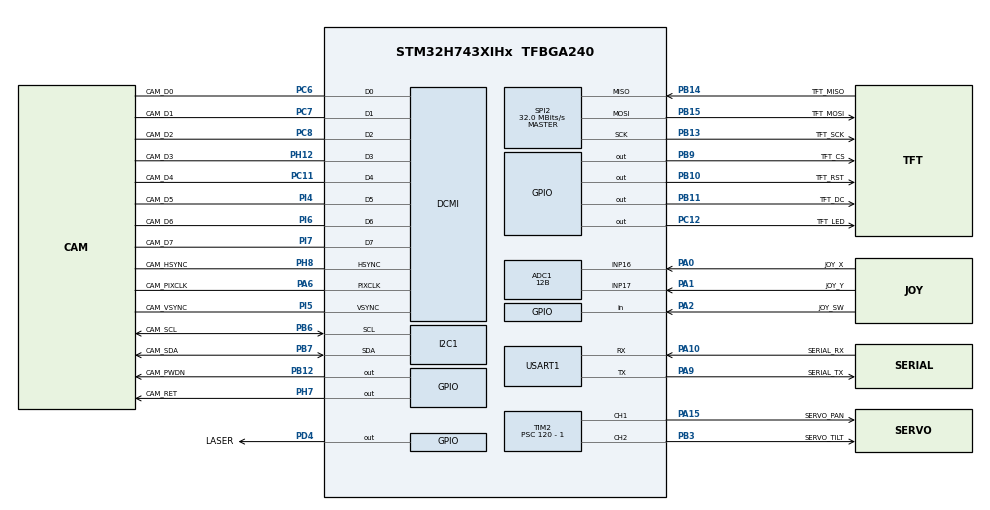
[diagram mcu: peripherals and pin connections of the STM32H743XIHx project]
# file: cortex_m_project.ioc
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ADC1.Channel-0\#ChannelRegularConversion=ADC_CHANNEL_16
ADC1.Channel-1\#ChannelRegularConversion=ADC_CHANNEL_17
ADC1.ClockPrescaler=ADC_CLOCK_ASYNC_DIV4
ADC1.ContinuousConvMode=ENABLE
ADC1.ConversionDataManagement=ADC_CONVERSIONDATA_DMA_CIRCULAR
ADC1.NbrOfConversion=2
ADC1.NbrOfConversionFlag=1
ADC1.OffsetNumber-0\#ChannelRegularConversion=ADC_OFFSET_NONE
ADC1.OffsetNumber-1\#ChannelRegularConversion=ADC_OFFSET_NONE
ADC1.OffsetSignedSaturation-0\#ChannelRegularConversion=DISABLE
ADC1.Rank-0\#ChannelRegularConversion=1
ADC1.Rank-1\#ChannelRegularConversion=2
ADC1.Resolution=ADC_RESOLUTION_12B
ADC1.SamplingTime-0\#ChannelRegularConversion=ADC_SAMPLETIME_64CYCLES_5
ADC1.SamplingTime-1\#ChannelRegularConversion=ADC_SAMPLETIME_64CYCLES_5
ADC1.master=1
CORTEX_M7.CPU_DCache=Enabled
CORTEX_M7.CPU_ICache=Enabled
CORTEX_M7.default_mode_Activation=1
DCMI.HSPolarity=DCMI_HSPOLARITY_LOW
DCMI.PCKPolarity=DCMI_PCKPOLARITY_RISING
DCMI.VSPolarity=DCMI_VSPOLARITY_LOW
Dma.ADC1.2.Direction=DMA_PERIPH_TO_MEMORY
Dma.ADC1.2.EventEnable=DISABLE
Dma.ADC1.2.FIFOMode=DMA_FIFOMODE_DISABLE
Dma.ADC1.2.Instance=DMA1_Stream2
Dma.ADC1.2.MemDataAlignment=DMA_MDATAALIGN_HALFWORD
Dma.ADC1.2.MemInc=DMA_MINC_ENABLE
Dma.ADC1.2.Mode=DMA_CIRCULAR
Dma.ADC1.2.PeriphDataAlignment=DMA_PDATAALIGN_HALFWORD
Dma.ADC1.2.PeriphInc=DMA_PINC_DISABLE
Dma.ADC1.2.Polarity=HAL_DMAMUX_REQ_GEN_RISING
Dma.ADC1.2.Priority=DMA_PRIORITY_LOW
Dma.ADC1.2.RequestNumber=1
Dma.ADC1.2.SignalID=NONE
Dma.ADC1.2.SyncEnable=DISABLE
Dma.ADC1.2.SyncPolarity=HAL_DMAMUX_SYNC_NO_EVENT
Dma.ADC1.2.SyncRequestNumber=1
Dma.ADC1.2.SyncSignalID=NONE
Dma.DCMI.0.Direction=DMA_PERIPH_TO_MEMORY
Dma.DCMI.0.EventEnable=DISABLE
Dma.DCMI.0.FIFOMode=DMA_FIFOMODE_ENABLE
Dma.DCMI.0.FIFOThreshold=DMA_FIFO_THRESHOLD_HALFFULL
Dma.DCMI.0.Instance=DMA1_Stream0
Dma.DCMI.0.MemBurst=DMA_MBURST_SINGLE
Dma.DCMI.0.MemDataAlignment=DMA_MDATAALIGN_WORD
Dma.DCMI.0.MemInc=DMA_MINC_ENABLE
Dma.DCMI.0.Mode=DMA_CIRCULAR
Dma.DCMI.0.PeriphBurst=DMA_PBURST_SINGLE
Dma.DCMI.0.PeriphDataAlignment=DMA_PDATAALIGN_WORD
Dma.DCMI.0.PeriphInc=DMA_PINC_DISABLE
Dma.DCMI.0.Polarity=HAL_DMAMUX_REQ_GEN_RISING
Dma.DCMI.0.Priority=DMA_PRIORITY_VERY_HIGH
Dma.DCMI.0.RequestNumber=1
Dma.DCMI.0.SignalID=NONE
Dma.DCMI.0.SyncEnable=DISABLE
Dma.DCMI.0.SyncPolarity=HAL_DMAMUX_SYNC_NO_EVENT
Dma.DCMI.0.SyncRequestNumber=1
Dma.DCMI.0.SyncSignalID=NONE
Dma.Request0=DCMI
Dma.Request1=SPI2_TX
Dma.Request2=ADC1
Dma.SPI2_TX.1.Direction=DMA_MEMORY_TO_PERIPH
Dma.SPI2_TX.1.EventEnable=DISABLE
Dma.SPI2_TX.1.FIFOMode=DMA_FIFOMODE_DISABLE
Dma.SPI2_TX.1.Instance=DMA1_Stream1
Dma.SPI2_TX.1.MemDataAlignment=DMA_MDATAALIGN_BYTE
Dma.SPI2_TX.1.MemInc=DMA_MINC_ENABLE
Dma.SPI2_TX.1.Mode=DMA_NORMAL
Dma.SPI2_TX.1.PeriphDataAlignment=DMA_PDATAALIGN_BYTE
Dma.SPI2_TX.1.PeriphInc=DMA_PINC_DISABLE
Dma.SPI2_TX.1.Polarity=HAL_DMAMUX_REQ_GEN_RISING
Dma.SPI2_TX.1.Priority=DMA_PRIORITY_MEDIUM
Dma.SPI2_TX.1.RequestNumber=1
Dma.SPI2_TX.1.SignalID=NONE
Dma.SPI2_TX.1.SyncEnable=DISABLE
Dma.SPI2_TX.1.SyncPolarity=HAL_DMAMUX_SYNC_NO_EVENT
Dma.SPI2_TX.1.SyncRequestNumber=1
Dma.SPI2_TX.1.SyncSignalID=NONE
FREERTOS.BinarySemaphores01=cameraFrameSem,Dynamic,NULL,Available
FREERTOS.Queues01=Queue1,1,12,1,Dynamic,NULL,NULL
FREERTOS.Tasks01=VisionTask,24,8192,StartVisionTask,Default,NULL,Dynamic,NULL,NULL;MotorTask,40,1024,StartMotorTask,Default,NULL,Dynamic,NULL,NULL
FREERTOS.configCHECK_FOR_STACK_OVERFLOW=2
FREERTOS.configTOTAL_HEAP_SIZE=131072
FREERTOS.configUSE_NEWLIB_REENTRANT=1
I2C1.Timing=0x307075B1
Mcu.Family=STM32H7
Mcu.Name=STM32H743XIHx
Mcu.Package=TFBGA240
NVIC.DCMI_IRQn=true\:5\:0\:false\:false\:true\:true\:true\:true\:true
NVIC.DMA1_Stream0_IRQn=true\:5\:0\:false\:false\:true\:true\:false\:true\:true
NVIC.DMA1_Stream1_IRQn=true\:5\:0\:false\:false\:true\:true\:false\:true\:true
NVIC.DMA1_Stream2_IRQn=true\:5\:0\:false\:false\:true\:true\:false\:true\:true
NVIC.PriorityGroup=NVIC_PRIORITYGROUP_4
NVIC.SPI2_IRQn=true\:5\:0\:false\:false\:true\:true\:true\:true\:true
NVIC.TIM6_DAC_IRQn=true\:15\:0\:false\:false\:true\:false\:false\:true\:true
NVIC.TimeBase=TIM6_DAC_IRQn
NVIC.TimeBaseIP=TIM6
NVIC.USART1_IRQn=true\:5\:0\:false\:false\:true\:true\:true\:true\:true
PA0.GPIO_Label=JOY_X
PA0.Mode=IN16-Single-Ended
PA0.Signal=ADC1_INP16
PA1.GPIO_Label=JOY_Y
PA1.Mode=IN17-Single-Ended
PA1.Signal=ADC1_INP17
PA10.GPIO_Label=SERIAL_RX
PA10.Mode=Asynchronous
PA10.Signal=USART1_RX
PA13\ (JTMS/SWDIO).Mode=Serial_Wire
PA13\ (JTMS/SWDIO).Signal=DEBUG_JTMS-SWDIO
PA14\ (JTCK/SWCLK).Mode=Serial_Wire
PA14\ (JTCK/SWCLK).Signal=DEBUG_JTCK-SWCLK
PA15\ (JTDI).GPIO_Label=SERVO_PAN
PA15\ (JTDI).Signal=S_TIM2_CH1_ETR
PA2.GPIO_Label=JOY_SW
PA2.GPIO_PuPd=GPIO_PULLUP
PA2.Signal=GPIO_Input
PA6.GPIO_Label=CAM_PIXCLK
PA6.GPIO_Speed=GPIO_SPEED_FREQ_VERY_HIGH
PA6.Mode=Slave_8_bits_External_Synchro
PA6.Signal=DCMI_PIXCLK
PA9.GPIO_Label=SERIAL_TX
PA9.Mode=Asynchronous
PA9.Signal=USART1_TX
PB10.GPIO_Label=TFT_RST
PB10.GPIO_Speed=GPIO_SPEED_FREQ_LOW
PB10.PinState=GPIO_PIN_SET
PB10.Signal=GPIO_Output
PB11.GPIO_Label=TFT_DC
PB11.GPIO_Speed=GPIO_SPEED_FREQ_HIGH
PB11.Signal=GPIO_Output
PB12.GPIO_Label=CAM_PWDN
PB12.Signal=GPIO_Output
PB13.GPIO_Label=TFT_SCK
PB13.Mode=Full_Duplex_Master
PB13.Signal=SPI2_SCK
PB14.GPIO_Label=TFT_MISO
PB14.Mode=Full_Duplex_Master
PB14.Signal=SPI2_MISO
PB15.GPIO_Label=TFT_MOSI
PB15.Mode=Full_Duplex_Master
PB15.Signal=SPI2_MOSI
PB3\ (JTDO/TRACESWO).GPIO_Label=SERVO_TILT
PB3\ (JTDO/TRACESWO).Signal=S_TIM2_CH2
PB6.GPIO_Label=CAM_SCL
PB6.GPIO_Pu=GPIO_PULLUP
PB6.Mode=I2C
PB6.Signal=I2C1_SCL
PB7.GPIO_Label=CAM_SDA
PB7.GPIO_Pu=GPIO_PULLUP
PB7.Mode=I2C
PB7.Signal=I2C1_SDA
PB9.GPIO_Label=TFT_CS
PB9.GPIO_Speed=GPIO_SPEED_FREQ_HIGH
PB9.PinState=GPIO_PIN_SET
PB9.Signal=GPIO_Output
PC11.GPIO_Label=CAM_D4
PC11.GPIO_Speed=GPIO_SPEED_FREQ_VERY_HIGH
PC11.Mode=Slave_8_bits_External_Synchro
PC11.Signal=DCMI_D4
PC12.GPIO_Label=TFT_LED
PC12.Signal=GPIO_Output
PC6.GPIO_Label=CAM_D0
PC6.GPIO_Speed=GPIO_SPEED_FREQ_VERY_HIGH
PC6.Mode=Slave_8_bits_External_Synchro
PC6.Signal=DCMI_D0
PC7.GPIO_Label=CAM_D1
PC7.GPIO_Speed=GPIO_SPEED_FREQ_VERY_HIGH
PC7.Mode=Slave_8_bits_External_Synchro
PC7.Signal=DCMI_D1
PC8.GPIO_Label=CAM_D2
PC8.GPIO_Speed=GPIO_SPEED_FREQ_VERY_HIGH
PC8.Mode=Slave_8_bits_External_Synchro
PC8.Signal=DCMI_D2
PD4.GPIO_Label=LASER
PD4.Signal=GPIO_Output
PH0-OSC_IN\ (PH0).Mode=HSE-External-Oscillator
PH0-OSC_IN\ (PH0).Signal=RCC_OSC_IN
PH1-OSC_OUT\ (PH1).Mode=HSE-External-Oscillator
PH1-OSC_OUT\ (PH1).Signal=RCC_OSC_OUT
PH12.GPIO_Label=CAM_D3
PH12.GPIO_Speed=GPIO_SPEED_FREQ_VERY_HIGH
PH12.Mode=Slave_8_bits_External_Synchro
PH12.Signal=DCMI_D3
PH7.GPIO_Label=CAM_RET
PH7.Signal=GPIO_Output
PH8.GPIO_Label=CAM_HSYNC
PH8.GPIO_Speed=GPIO_SPEED_FREQ_VERY_HIGH
PH8.Mode=Slave_8_bits_External_Synchro
PH8.Signal=DCMI_HSYNC
PI4.GPIO_Label=CAM_D5
PI4.GPIO_Speed=GPIO_SPEED_FREQ_VERY_HIGH
PI4.Mode=Slave_8_bits_External_Synchro
PI4.Signal=DCMI_D5
PI5.GPIO_Label=CAM_VSYNC
PI5.GPIO_Speed=GPIO_SPEED_FREQ_VERY_HIGH
PI5.Mode=Slave_8_bits_External_Synchro
PI5.Signal=DCMI_VSYNC
PI6.GPIO_Label=CAM_D6
PI6.GPIO_Speed=GPIO_SPEED_FREQ_VERY_HIGH
PI6.Mode=Slave_8_bits_External_Synchro
PI6.Signal=DCMI_D6
PI7.GPIO_Label=CAM_D7
PI7.GPIO_Speed=GPIO_SPEED_FREQ_VERY_HIGH
PI7.Mode=Slave_8_bits_External_Synchro
PI7.Signal=DCMI_D7
ProjectManager.HeapSize=0x20000
ProjectManager.StackSize=0x1000
ProjectManager.TargetToolchain=STM32CubeIDE
RCC.ADCFreq_Value=75000000
RCC.APB1Freq_Value=120000000
RCC.APB2Freq_Value=120000000
RCC.APB3Freq_Value=120000000
RCC.APB4Freq_Value=120000000
RCC.CortexFreq_Value=480000000
RCC.DIVM1=5
RCC.DIVM2=2
RCC.DIVN1=192
RCC.DIVN2=12
RCC.HCLKFreq_Value=120000000
RCC.HPRE=RCC_HCLK_DIV4
RCC.PLL2FRACN=0
RCC.PLL3FRACN=0
RCC.PLLFRACN=0
RCC.PLLSourceVirtual=RCC_PLLSOURCE_HSE
RCC.RCC_MCO1Source=RCC_MCO1SOURCE_HSE
RCC.RCC_MCODiv1=RCC_MCODIV_2
RCC.SPI123CLockSelection=RCC_SPI123CLKSOURCE_CLKP
RCC.SYSCLKFreq_VALUE=480000000
RCC.SYSCLKSource=RCC_SYSCLKSOURCE_PLLCLK
RCC.USBFreq_Value=480000000
SH.S_TIM2_CH1_ETR.0=TIM2_CH1,PWM Generation1 CH1
SH.S_TIM2_CH2.0=TIM2_CH2,PWM Generation2 CH2
SPI2.BaudRatePrescaler=SPI_BAUDRATEPRESCALER_2
SPI2.CalculateBaudRate=32.0 MBits/s
SPI2.DataSize=SPI_DATASIZE_8BIT
SPI2.Direction=SPI_DIRECTION_2LINES
SPI2.Mode=SPI_MODE_MASTER
SPI2.NSSPMode=SPI_NSS_PULSE_DISABLE
SPI2.VirtualType=VM_MASTER
TIM2.Channel-PWM\ Generation1\ CH1=TIM_CHANNEL_1
TIM2.Channel-PWM\ Generation2\ CH2=TIM_CHANNEL_2
TIM2.Period=20000 - 1
TIM2.Prescaler=120 - 1
TIM2.Pulse-PWM\ Generation1\ CH1=1500
TIM2.Pulse-PWM\ Generation2\ CH2=1500
USART1.VirtualMode-Asynchronous=VM_ASYNC
VP_FREERTOS_VS_CMSIS_V2.Mode=CMSIS_V2
VP_MEMORYMAP_VS_MEMORYMAP.Mode=CurAppReg
VP_SYS_VS_tim6.Mode=TIM6
VP_TIM2_VS_ClockSourceINT.Mode=Internal
board=custom

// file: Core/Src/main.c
/* USER CODE BEGIN Header */
/**
  ******************************************************************************
  * @file           : main.c
  * @brief          : Main program body
  ******************************************************************************
  * @attention
  *
  * Copyright (c) 2026 STMicroelectronics.
  * All rights reserved.
  *
  * This software is licensed under terms that can be found in the LICENSE file
  * in the root directory of this software component.
  * If no LICENSE file comes with this software, it is provided AS-IS.
  *
  ******************************************************************************
  */
/* USER CODE END Header */
#include "main.h"
#include "FreeRTOS.h"
#include "cmsis_os2.h"
#include "adc.h"
#include "dcmi.h"
#include "dma.h"
#include "i2c.h"
#include "spi.h"
#include "tim.h"
#include "usart.h"
#include "gpio.h"

/* USER CODE BEGIN Includes */
#include "app_main.h"
/* USER CODE END Includes */

void SystemClock_Config(void);
void PeriphCommonClock_Config(void);
static void MPU_Config(void);
void MX_FREERTOS_Init(void);

int main(void)
{

  /* MPU Configuration--------------------------------------------------------*/
  MPU_Config();

  /* Enable the CPU Cache */

  /* Enable I-Cache---------------------------------------------------------*/
  SCB_EnableICache();

  /* Enable D-Cache---------------------------------------------------------*/
  SCB_EnableDCache();

  /* MCU Configuration--------------------------------------------------------*/

  /* Reset of all peripherals, Initializes the Flash interface and the Systick. */
  HAL_Init();

  /* Configure the system clock */
  SystemClock_Config();

  /* Configure the peripherals common clocks */
  PeriphCommonClock_Config();

  /* Initialize all configured peripherals */
  MX_GPIO_Init();
  MX_DMA_Init();
  MX_USART1_UART_Init();
  MX_DCMI_Init();
  MX_I2C1_Init();
  MX_TIM2_Init();
  MX_SPI2_Init();
  MX_ADC1_Init();

  /* Init scheduler */
  osKernelInitialize();  /* Call init function for freertos objects (in cmsis_os2.c) */
  MX_FREERTOS_Init();

  /* Start scheduler */
  osKernelStart();

  /* We should never get here as control is now taken by the scheduler */

  /* Infinite loop */
  while (1)
  {

  }
}

void SystemClock_Config(void)
{
  RCC_OscInitTypeDef RCC_OscInitStruct = {0};
  RCC_ClkInitTypeDef RCC_ClkInitStruct = {0};

  /** Supply configuration update enable
  */
  HAL_PWREx_ConfigSupply(PWR_LDO_SUPPLY);

  /** Configure the main internal regulator output voltage
  */
  __HAL_PWR_VOLTAGESCALING_CONFIG(PWR_REGULATOR_VOLTAGE_SCALE0);

  while(!__HAL_PWR_GET_FLAG(PWR_FLAG_VOSRDY)) {}

  /** Initializes the RCC Oscillators according to the specified parameters
  * in the RCC_OscInitTypeDef structure.
  */
  RCC_OscInitStruct.OscillatorType = RCC_OSCILLATORTYPE_HSI|RCC_OSCILLATORTYPE_HSE;
  RCC_OscInitStruct.HSEState = RCC_HSE_ON;
  RCC_OscInitStruct.HSIState = RCC_HSI_DIV1;
  RCC_OscInitStruct.HSICalibrationValue = RCC_HSICALIBRATION_DEFAULT;
  RCC_OscInitStruct.PLL.PLLState = RCC_PLL_ON;
  RCC_OscInitStruct.PLL.PLLSource = RCC_PLLSOURCE_HSE;
  RCC_OscInitStruct.PLL.PLLM = 5;
  RCC_OscInitStruct.PLL.PLLN = 192;
  RCC_OscInitStruct.PLL.PLLP = 2;
  RCC_OscInitStruct.PLL.PLLQ = 2;
  RCC_OscInitStruct.PLL.PLLR = 2;
  RCC_OscInitStruct.PLL.PLLRGE = RCC_PLL1VCIRANGE_2;
  RCC_OscInitStruct.PLL.PLLVCOSEL = RCC_PLL1VCOWIDE;
  RCC_OscInitStruct.PLL.PLLFRACN = 0;
  if (HAL_RCC_OscConfig(&RCC_OscInitStruct) != HAL_OK)
  {
    Error_Handler();
  }

  /** Initializes the CPU, AHB and APB buses clocks
  */
  RCC_ClkInitStruct.ClockType = RCC_CLOCKTYPE_HCLK|RCC_CLOCKTYPE_SYSCLK
                              |RCC_CLOCKTYPE_PCLK1|RCC_CLOCKTYPE_PCLK2
                              |RCC_CLOCKTYPE_D3PCLK1|RCC_CLOCKTYPE_D1PCLK1;
  RCC_ClkInitStruct.SYSCLKSource = RCC_SYSCLKSOURCE_PLLCLK;
  RCC_ClkInitStruct.SYSCLKDivider = RCC_SYSCLK_DIV1;
  RCC_ClkInitStruct.AHBCLKDivider = RCC_HCLK_DIV4;
  RCC_ClkInitStruct.APB3CLKDivider = RCC_APB3_DIV1;
  RCC_ClkInitStruct.APB1CLKDivider = RCC_APB1_DIV1;
  RCC_ClkInitStruct.APB2CLKDivider = RCC_APB2_DIV1;
  RCC_ClkInitStruct.APB4CLKDivider = RCC_APB4_DIV1;

  if (HAL_RCC_ClockConfig(&RCC_ClkInitStruct, FLASH_LATENCY_1) != HAL_OK)
  {
    Error_Handler();
  }
}

void PeriphCommonClock_Config(void)
{
  RCC_PeriphCLKInitTypeDef PeriphClkInitStruct = {0};

  /** Initializes the peripherals clock
  */
  PeriphClkInitStruct.PeriphClockSelection = RCC_PERIPHCLK_CKPER;
  PeriphClkInitStruct.CkperClockSelection = RCC_CLKPSOURCE_HSI;
  if (HAL_RCCEx_PeriphCLKConfig(&PeriphClkInitStruct) != HAL_OK)
  {
    Error_Handler();
  }
}

 /* MPU Configuration */

void MPU_Config(void)
{
  MPU_Region_InitTypeDef MPU_InitStruct = {0};

  /* Disables the MPU */
  HAL_MPU_Disable();

  /** Initializes and configures the Region and the memory to be protected
  */
  MPU_InitStruct.Enable = MPU_REGION_ENABLE;
  MPU_InitStruct.Number = MPU_REGION_NUMBER0;
  MPU_InitStruct.BaseAddress = 0x0;
  MPU_InitStruct.Size = MPU_REGION_SIZE_4GB;
  MPU_InitStruct.SubRegionDisable = 0x87;
  MPU_InitStruct.TypeExtField = MPU_TEX_LEVEL0;
  MPU_InitStruct.AccessPermission = MPU_REGION_NO_ACCESS;
  MPU_InitStruct.DisableExec = MPU_INSTRUCTION_ACCESS_DISABLE;
  MPU_InitStruct.IsShareable = MPU_ACCESS_SHAREABLE;
  MPU_InitStruct.IsCacheable = MPU_ACCESS_NOT_CACHEABLE;
  MPU_InitStruct.IsBufferable = MPU_ACCESS_NOT_BUFFERABLE;

  HAL_MPU_ConfigRegion(&MPU_InitStruct);
  /* Enables the MPU */
  HAL_MPU_Enable(MPU_PRIVILEGED_DEFAULT);

}

void HAL_TIM_PeriodElapsedCallback(TIM_HandleTypeDef *htim)
{
  if (htim->Instance == TIM6)
  {
    HAL_IncTick();
  }
}

void Error_Handler(void)
{
  __disable_irq();
  while (1)
  {
  }
}

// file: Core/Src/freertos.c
/* USER CODE BEGIN Header */
/**
  ******************************************************************************
  * File Name          : freertos.c
  * Description        : Code for freertos applications
  ******************************************************************************
  * @attention
  *
  * Copyright (c) 2026 STMicroelectronics.
  * All rights reserved.
  *
  * This software is licensed under terms that can be found in the LICENSE file
  * in the root directory of this software component.
  * If no LICENSE file comes with this software, it is provided AS-IS.
  *
  ******************************************************************************
  */
/* USER CODE END Header */

#include "FreeRTOS.h"
#include "task.h"
#include "main.h"
#include "FreeRTOS.h"
#include "cmsis_os2.h"

/* USER CODE BEGIN Includes */

#include "app_main.h"
#include "task_vision.h"
#include "task_motor.h"

/* USER CODE END Includes */

/* Definitions for VisionTask */
osThreadId_t VisionTaskHandle;
const osThreadAttr_t VisionTask_attributes = {
  .name = "VisionTask",
  .stack_size = 8192 * 4,
  .priority = (osPriority_t) osPriorityNormal,
};
/* Definitions for MotorTask */
osThreadId_t MotorTaskHandle;
const osThreadAttr_t MotorTask_attributes = {
  .name = "MotorTask",
  .stack_size = 1024 * 4,
  .priority = (osPriority_t) osPriorityHigh,
};
/* Definitions for Queue1 */
osMessageQueueId_t Queue1Handle;
const osMessageQueueAttr_t Queue1_attributes = {
  .name = "Queue1"
};
/* Definitions for cameraFrameSem */
osSemaphoreId_t cameraFrameSemHandle;
const osSemaphoreAttr_t cameraFrameSem_attributes = {
  .name = "cameraFrameSem"
};

void StartVisionTask(void *argument);
void StartMotorTask(void *argument);

void MX_FREERTOS_Init(void); /* (MISRA C 2004 rule 8.1) */

/* Hook prototypes */
void vApplicationStackOverflowHook(xTaskHandle xTask, char *pcTaskName);

/* USER CODE BEGIN 4 */
void vApplicationStackOverflowHook(xTaskHandle xTask, char *pcTaskName)
{
   /* Run time stack overflow checking is performed if
   configCHECK_FOR_STACK_OVERFLOW is defined to 1 or 2. This hook function is
   called if a stack overflow is detected. */
}
/* USER CODE END 4 */

void MX_FREERTOS_Init(void) {

  /* Create the semaphores(s) */
  /* creation of cameraFrameSem */
  cameraFrameSemHandle = osSemaphoreNew(1, 1, &cameraFrameSem_attributes);

  /* Create the queue(s) */
  /* creation of Queue1 */
  Queue1Handle = osMessageQueueNew (1, 12, &Queue1_attributes);

  /* Create the thread(s) */
  /* creation of VisionTask */
  VisionTaskHandle = osThreadNew(StartVisionTask, NULL, &VisionTask_attributes);

  /* creation of MotorTask */
  MotorTaskHandle = osThreadNew(StartMotorTask, NULL, &MotorTask_attributes);

}

void StartVisionTask(void *argument)
{
  /* USER CODE BEGIN StartVisionTask */
	VisionTask();

  /* Infinite loop */
  for(;;)
  {
    osDelay(1);
  }
  /* USER CODE END StartVisionTask */
}

void StartMotorTask(void *argument)
{
  /* USER CODE BEGIN StartMotorTask */
    MotorTask();

  /* Infinite loop */
  for(;;)
  {
    osDelay(1);
  }
  /* USER CODE END StartMotorTask */
}
